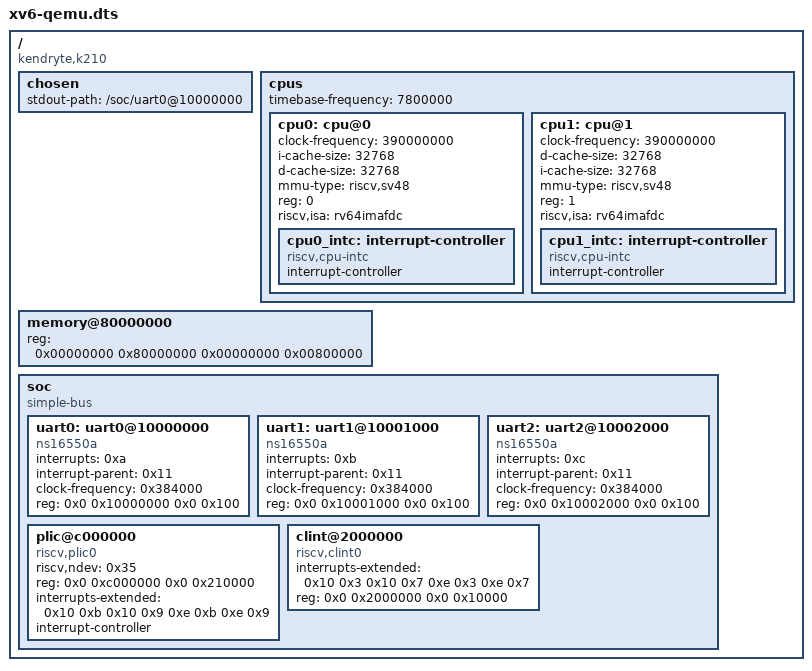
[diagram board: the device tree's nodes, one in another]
/*
 * SPDX-License-Identifier: BSD-2-Clause
 *
 * Copyright (c) 2019 Western Digital Corporation or its affiliates.
 *
 * Authors:
 *   Damien Le Moal <damien.lemoal@wdc.com>
 */

/dts-v1/;
/ {
	#address-cells = <2>;
	#size-cells = <2>;
	compatible = "kendryte,k210";

	chosen {
        // bootargs = "console=hvc0 earlycon=sbi";
		stdout-path = "/soc/uart0@10000000";
	};

	cpus {
		#address-cells = <1>;
		#size-cells = <0>;
		timebase-frequency = <7800000>;

		cpu0: cpu@0 {
			phandle = <0xf>;
			device_type = "cpu";
			clock-frequency = <390000000>;
			i-cache-size = <32768>;
			d-cache-size = <32768>;
			mmu-type = "riscv,sv48";
			reg = <0>;
			riscv,isa = "rv64imafdc";
			status = "okay";

			cpu0_intc: interrupt-controller {
				#interrupt-cells = <1>;
				compatible = "riscv,cpu-intc";
				interrupt-controller;
				phandle = <0x10>;
			};
		};
		cpu1: cpu@1 {
			phandle = <0xd>;
			device_type = "cpu";
			clock-frequency = <390000000>;
			d-cache-size = <32768>;
			i-cache-size = <32768>;
			mmu-type = "riscv,sv48";
			reg = <1>;
			riscv,isa = "rv64imafdc";
			status = "okay";

			cpu1_intc: interrupt-controller {
				#interrupt-cells = <1>;
				compatible = "riscv,cpu-intc";
				interrupt-controller;
				phandle = <0xe>;
			};
		};
	};

	memory@80000000 {
		/* Bank 0: 4 MB, Bank 1: 2 MB, AI chip SRAM: 2MB */
		device_type = "memory";
		reg = <0x00000000 0x80000000 0x00000000 0x00800000>;
	};

	soc {
		#address-cells = <0x2>;
		#size-cells = <0x2>;
		compatible = "simple-bus";
		ranges;

		uart0: uart0@10000000 {
			interrupts = <0xa>;
			interrupt-parent = <0x11>;
			clock-frequency = <0x384000>;
			reg = <0x0 0x10000000 0x0 0x100>;
			compatible = "ns16550a";
		};

		uart1: uart1@10001000 {
			interrupts = <0xb>;
			interrupt-parent = <0x11>;
			clock-frequency = <0x384000>;
			reg = <0x0 0x10001000 0x0 0x100>;
			compatible = "ns16550a";
		};

        uart2: uart2@10002000 {
			interrupts = <0xc>;
			interrupt-parent = <0x11>;
			clock-frequency = <0x384000>;
			reg = <0x0 0x10002000 0x0 0x100>;
			compatible = "ns16550a";
		};

		plic@c000000 {
			phandle = <0x11>;
			riscv,ndev = <0x35>;
			reg = <0x0 0xc000000 0x0 0x210000>;
			interrupts-extended = <0x10 0xb 0x10 0x9 0xe 0xb 0xe 0x9>;
			interrupt-controller;
			compatible = "riscv,plic0";
			#interrupt-cells = <0x1>;
			#address-cells = <0x0>;
		};

		clint@2000000 {
			interrupts-extended = <0x10 0x3 0x10 0x7 0xe 0x3 0xe 0x7>;
			reg = <0x0 0x2000000 0x0 0x10000>;
			compatible = "riscv,clint0";
		};
	};
};
